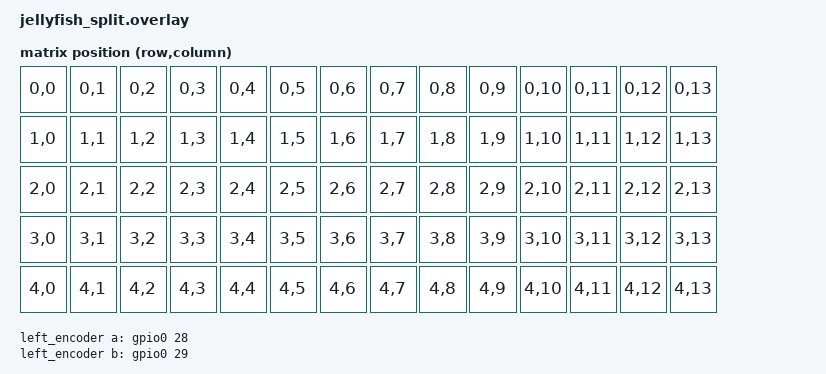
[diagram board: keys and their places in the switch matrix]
// This file was generated from a template. Edit it to match your keyboard.
// See https://zmk.dev/docs/development/hardware-integration/new-shield for more
// instructions.

#include <dt-bindings/zmk/matrix_transform.h>
#include <dt-bindings/led/led.h>

/ {
    chosen {
        zmk,kscan = &kscan0;
        zmk,matrix-transform = &default_transform;
    };

    default_transform: keymap_transform0 {
        compatible = "zmk,matrix-transform";
        columns = <14>;
        rows = <5>;
        map = <
            RC(0,0) RC(0,1) RC(0,2) RC(0,3) RC(0,4) RC(0,5) RC(0,6)  RC(0,7) RC(0,8) RC(0,9) RC(0,10) RC(0,11) RC(0,12) RC(0,13)
            RC(1,0) RC(1,1) RC(1,2) RC(1,3) RC(1,4) RC(1,5) RC(1,6)  RC(1,7) RC(1,8) RC(1,9) RC(1,10) RC(1,11) RC(1,12) RC(1,13)
            RC(2,0) RC(2,1) RC(2,2) RC(2,3) RC(2,4) RC(2,5) RC(2,6)  RC(2,7) RC(2,8) RC(2,9) RC(2,10) RC(2,11) RC(2,12) RC(2,13)
            RC(3,0) RC(3,1) RC(3,2) RC(3,3) RC(3,4) RC(3,5) RC(3,6)  RC(3,7) RC(3,8) RC(3,9) RC(3,10) RC(3,11) RC(3,12) RC(3,13)
            RC(4,0) RC(4,1) RC(4,2) RC(4,3) RC(4,4) RC(4,5) RC(4,6)  RC(4,7) RC(4,8) RC(4,9) RC(4,10) RC(4,11) RC(4,12) RC(4,13)
        >;
    };
    
    // kscan0 の「枠組み」宣言する
    kscan0: kscan {
        compatible = "zmk,kscan-gpio-matrix";
    };
};

/* エンコーダーの定義 */
/ {
    /* エンコーダーの定義 */
    left_encoder: encoder_left {
        compatible = "alps,ec11";
        a-gpios = <&gpio0 28 (GPIO_ACTIVE_LOW | GPIO_PULL_UP)>; // D2 (P0.28)
        b-gpios = <&gpio0 29 (GPIO_ACTIVE_LOW | GPIO_PULL_UP)>; // D3 (P0.29)
        steps = <80>;
    };

    sensors: sensors {
        compatible = "zmk,keymap-sensors";
        sensors = <&left_encoder>;
        triggers-per-rotation = <20>;
    };
};

/* P0.02 (D0) を LED信号(MOSI) に指定 */
&pinctrl {
    spi0_default: spi0_default {
        group1 {
            psels = <NRF_PSEL(SPIM_MOSI, 0, 2)>; // P0.02 = D0
        };
    };
    spi0_sleep: spi0_sleep {
        group1 {
            psels = <NRF_PSEL(SPIM_MOSI, 0, 2)>;
            low-power-enable;
        };
    };
};

/* SPI設定とLED */
&spi0 {
    compatible = "nordic,nrf-spim";
    status = "okay";
    pinctrl-0 = <&spi0_default>;
    pinctrl-1 = <&spi0_sleep>;
    pinctrl-names = "default", "sleep";

    /* ルート直下からここに移動させました */
    led_strip: ws2812@0 {
        compatible = "worldsemi,ws2812-spi";
        reg = <0>;
        spi-max-frequency = <4000000>;
        chain-length = <28>; 
        spi-one-frame = <0x70>;
        spi-zero-frame = <0x40>;
        color-mapping = <LED_COLOR_ID_GREEN LED_COLOR_ID_RED LED_COLOR_ID_BLUE>;
    };
};

// 本体のLEDインジケータ（必要に応じて）
&led0 { status = "okay"; }; // Blue (P1.03)
&led1 { status = "okay"; }; // Red (P1.05)
&led2 { status = "okay"; }; // Green (P1.07)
